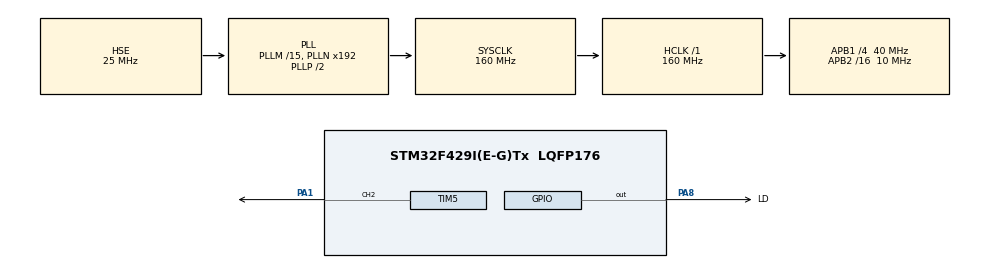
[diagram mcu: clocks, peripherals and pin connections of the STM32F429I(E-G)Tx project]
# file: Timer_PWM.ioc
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Mcu.Family=STM32F4
Mcu.Name=STM32F429I(E-G)Tx
Mcu.Package=LQFP176
NVIC.PriorityGroup=NVIC_PRIORITYGROUP_4
NVIC.TIM3_IRQn=true\:0\:0\:false\:false\:true\:true\:true
NVIC.TIM5_IRQn=true\:0\:0\:false\:false\:true\:true\:true
PA1.Signal=S_TIM5_CH2
PA13.Mode=Serial_Wire
PA13.Signal=SYS_JTMS-SWDIO
PA14.Mode=Serial_Wire
PA14.Signal=SYS_JTCK-SWCLK
PA8.GPIO_Label=LD
PA8.Signal=GPIO_Output
PH0/OSC_IN.Mode=HSE-External-Oscillator
PH0/OSC_IN.Signal=RCC_OSC_IN
PH1/OSC_OUT.Mode=HSE-External-Oscillator
PH1/OSC_OUT.Signal=RCC_OSC_OUT
ProjectManager.HeapSize=0x2000
ProjectManager.StackSize=0x4000
ProjectManager.TargetToolchain=STM32CubeIDE
RCC.48MHZClocksFreq_Value=64000000
RCC.AHBFreq_Value=160000000
RCC.APB1CLKDivider=RCC_HCLK_DIV4
RCC.APB1Freq_Value=40000000
RCC.APB1TimFreq_Value=80000000
RCC.APB2CLKDivider=RCC_HCLK_DIV16
RCC.APB2Freq_Value=10000000
RCC.APB2TimFreq_Value=20000000
RCC.CortexFreq_Value=160000000
RCC.HCLKFreq_Value=160000000
RCC.HSE_VALUE=25000000
RCC.HSI_VALUE=16000000
RCC.LSE_VALUE=32768
RCC.PLLM=15
RCC.PLLQ=5
RCC.PLLSourceVirtual=RCC_PLLSOURCE_HSE
RCC.SYSCLKFreq_VALUE=160000000
RCC.SYSCLKSource=RCC_SYSCLKSOURCE_PLLCLK
RCC.VCOOutputFreq_Value=320000000
SH.S_TIM5_CH2.0=TIM5_CH2,PWM Generation2 CH2
TIM3.Period=1599
TIM3.TIM_MasterSlaveMode=TIM_MASTERSLAVEMODE_DISABLE
TIM5.Channel-PWM\ Generation2\ CH2=TIM_CHANNEL_2
TIM5.Period=49999
TIM5.Pulse-PWM\ Generation2\ CH2=799
TIM5.TIM_MasterOutputTrigger=TIM_TRGO_UPDATE
TIM5.TIM_MasterSlaveMode=TIM_MASTERSLAVEMODE_ENABLE
VP_TIM3_VS_ClockSourceITR.Mode=TriggerSource_ITR2
VP_TIM3_VS_ControllerModeClock.Mode=Clock Mode
VP_TIM5_VS_ClockSourceINT.Mode=Internal
board=custom

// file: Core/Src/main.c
/* USER CODE BEGIN Header */
/**
  ******************************************************************************
  * @file           : main.c
  * @brief          : Main program body
  ******************************************************************************
  * @attention
  *
  * <h2><center>&copy; Copyright (c) 2021 STMicroelectronics.
  * All rights reserved.</center></h2>
  *
  * This software component is licensed by ST under Ultimate Liberty license
  * SLA0044, the "License"; You may not use this file except in compliance with
  * the License. You may obtain a copy of the License at:
  *                             www.st.com/SLA0044
  *
  ******************************************************************************
  */
/* USER CODE END Header */
#include "main.h"

TIM_HandleTypeDef htim3;
TIM_HandleTypeDef htim5;

void SystemClock_Config(void);
static void MX_GPIO_Init(void);
static void MX_TIM5_Init(void);
static void MX_TIM3_Init(void);

/* USER CODE BEGIN 0 */
//float Grap[10] = {615,    //1,194
//		302.5,			  //2,193
//		198.3,            //3,192
//		149.25,           //4,191
//		115,              //5-190
//		1230              198.3//195
//};
uint32_t Calculator_Grap_clock_num(uint8_t clock_in,float GrapUstime)
{
	return clock_in*GrapUstime;
}

void Tim_set_period(float PeriodUs)
{

	__HAL_TIM_SET_AUTORELOAD(&htim5,Calculator_Grap_clock_num(80,PeriodUs)-1);
	__HAL_TIM_SET_COUNTER(&htim5,0);
}
void Tim_set_time_high(float PeriodUs) //10s
{
	__HAL_TIM_SET_COMPARE(&htim5,TIM_CHANNEL_2,Calculator_Grap_clock_num(80,PeriodUs)-1);
}
uint8_t Time3_cnt;
void swich_new_grap()
{
	Time3_cnt ++;
	if(Time3_cnt == 196)
		Time3_cnt = 1;
	switch (Time3_cnt) {
		case 1:
		case 194:
			Tim_set_period(615+10);
			break;
		case 2:
		case 193:
			Tim_set_period(302.5+10);
			break;
		case 3:
		case 192:
			Tim_set_period(198.3+10);
			break;
		case 4:
		case 191:
			Tim_set_period(149.25+10);
			break;
		case 195:
			Tim_set_period(1230+10);
			break;
		default:
			Tim_set_period(115+10);
			break;
	}
}
void HAL_TIM_PeriodElapsedCallback(TIM_HandleTypeDef *htim)
{
	if(htim->Instance == htim3.Instance)
	{
		swich_new_grap();
		HAL_GPIO_TogglePin(LD_GPIO_Port, LD_Pin);
	}
}

/* USER CODE END 0 */

int main(void)
{

  /* MCU Configuration--------------------------------------------------------*/

  /* Reset of all peripherals, Initializes the Flash interface and the Systick. */
  HAL_Init();

  /* Configure the system clock */
  SystemClock_Config();

  /* Initialize all configured peripherals */
  MX_GPIO_Init();
  MX_TIM5_Init();
  MX_TIM3_Init();
  /* USER CODE BEGIN 2 */
  Tim_set_time_high(10);
  swich_new_grap();
  HAL_TIM_PWM_Start(&htim5, TIM_CHANNEL_2);
  HAL_TIM_Base_Start_IT(&htim3);
  /* USER CODE END 2 */

  /* Infinite loop */
  /* USER CODE BEGIN WHILE */
  while (1)
  {
	  HAL_GPIO_TogglePin(LD_GPIO_Port, LD_Pin);
	  HAL_Delay(200);
    /* USER CODE END WHILE */

  }
}

void SystemClock_Config(void)
{
  RCC_OscInitTypeDef RCC_OscInitStruct = {0};
  RCC_ClkInitTypeDef RCC_ClkInitStruct = {0};

  /** Configure the main internal regulator output voltage
  */
  __HAL_RCC_PWR_CLK_ENABLE();
  __HAL_PWR_VOLTAGESCALING_CONFIG(PWR_REGULATOR_VOLTAGE_SCALE1);
  /** Initializes the RCC Oscillators according to the specified parameters
  * in the RCC_OscInitTypeDef structure.
  */
  RCC_OscInitStruct.OscillatorType = RCC_OSCILLATORTYPE_HSE;
  RCC_OscInitStruct.HSEState = RCC_HSE_ON;
  RCC_OscInitStruct.PLL.PLLState = RCC_PLL_ON;
  RCC_OscInitStruct.PLL.PLLSource = RCC_PLLSOURCE_HSE;
  RCC_OscInitStruct.PLL.PLLM = 15;
  RCC_OscInitStruct.PLL.PLLN = 192;
  RCC_OscInitStruct.PLL.PLLP = RCC_PLLP_DIV2;
  RCC_OscInitStruct.PLL.PLLQ = 5;
  if (HAL_RCC_OscConfig(&RCC_OscInitStruct) != HAL_OK)
  {
    Error_Handler();
  }
  /** Initializes the CPU, AHB and APB buses clocks
  */
  RCC_ClkInitStruct.ClockType = RCC_CLOCKTYPE_HCLK|RCC_CLOCKTYPE_SYSCLK
                              |RCC_CLOCKTYPE_PCLK1|RCC_CLOCKTYPE_PCLK2;
  RCC_ClkInitStruct.SYSCLKSource = RCC_SYSCLKSOURCE_PLLCLK;
  RCC_ClkInitStruct.AHBCLKDivider = RCC_SYSCLK_DIV1;
  RCC_ClkInitStruct.APB1CLKDivider = RCC_HCLK_DIV4;
  RCC_ClkInitStruct.APB2CLKDivider = RCC_HCLK_DIV16;

  if (HAL_RCC_ClockConfig(&RCC_ClkInitStruct, FLASH_LATENCY_5) != HAL_OK)
  {
    Error_Handler();
  }
}

static void MX_TIM3_Init(void)
{

  TIM_SlaveConfigTypeDef sSlaveConfig = {0};
  TIM_MasterConfigTypeDef sMasterConfig = {0};

  htim3.Instance = TIM3;
  htim3.Init.Prescaler = 0;
  htim3.Init.CounterMode = TIM_COUNTERMODE_UP;
  htim3.Init.Period = 1599;
  htim3.Init.ClockDivision = TIM_CLOCKDIVISION_DIV1;
  htim3.Init.AutoReloadPreload = TIM_AUTORELOAD_PRELOAD_DISABLE;
  if (HAL_TIM_Base_Init(&htim3) != HAL_OK)
  {
    Error_Handler();
  }
  sSlaveConfig.SlaveMode = TIM_SLAVEMODE_EXTERNAL1;
  sSlaveConfig.InputTrigger = TIM_TS_ITR2;
  if (HAL_TIM_SlaveConfigSynchro(&htim3, &sSlaveConfig) != HAL_OK)
  {
    Error_Handler();
  }
  sMasterConfig.MasterOutputTrigger = TIM_TRGO_RESET;
  sMasterConfig.MasterSlaveMode = TIM_MASTERSLAVEMODE_DISABLE;
  if (HAL_TIMEx_MasterConfigSynchronization(&htim3, &sMasterConfig) != HAL_OK)
  {
    Error_Handler();
  }

}

static void MX_TIM5_Init(void)
{

  TIM_ClockConfigTypeDef sClockSourceConfig = {0};
  TIM_MasterConfigTypeDef sMasterConfig = {0};
  TIM_OC_InitTypeDef sConfigOC = {0};

  htim5.Instance = TIM5;
  htim5.Init.Prescaler = 0;
  htim5.Init.CounterMode = TIM_COUNTERMODE_UP;
  htim5.Init.Period = 49999;
  htim5.Init.ClockDivision = TIM_CLOCKDIVISION_DIV1;
  htim5.Init.AutoReloadPreload = TIM_AUTORELOAD_PRELOAD_DISABLE;
  if (HAL_TIM_Base_Init(&htim5) != HAL_OK)
  {
    Error_Handler();
  }
  sClockSourceConfig.ClockSource = TIM_CLOCKSOURCE_INTERNAL;
  if (HAL_TIM_ConfigClockSource(&htim5, &sClockSourceConfig) != HAL_OK)
  {
    Error_Handler();
  }
  if (HAL_TIM_PWM_Init(&htim5) != HAL_OK)
  {
    Error_Handler();
  }
  sMasterConfig.MasterOutputTrigger = TIM_TRGO_UPDATE;
  sMasterConfig.MasterSlaveMode = TIM_MASTERSLAVEMODE_ENABLE;
  if (HAL_TIMEx_MasterConfigSynchronization(&htim5, &sMasterConfig) != HAL_OK)
  {
    Error_Handler();
  }
  sConfigOC.OCMode = TIM_OCMODE_PWM1;
  sConfigOC.Pulse = 799;
  sConfigOC.OCPolarity = TIM_OCPOLARITY_HIGH;
  sConfigOC.OCFastMode = TIM_OCFAST_DISABLE;
  if (HAL_TIM_PWM_ConfigChannel(&htim5, &sConfigOC, TIM_CHANNEL_2) != HAL_OK)
  {
    Error_Handler();
  }
  HAL_TIM_MspPostInit(&htim5);

}

static void MX_GPIO_Init(void)
{
  GPIO_InitTypeDef GPIO_InitStruct = {0};

  /* GPIO Ports Clock Enable */
  __HAL_RCC_GPIOH_CLK_ENABLE();
  __HAL_RCC_GPIOA_CLK_ENABLE();

  /*Configure GPIO pin Output Level */
  HAL_GPIO_WritePin(LD_GPIO_Port, LD_Pin, GPIO_PIN_RESET);

  /*Configure GPIO pin : LD_Pin */
  GPIO_InitStruct.Pin = LD_Pin;
  GPIO_InitStruct.Mode = GPIO_MODE_OUTPUT_PP;
  GPIO_InitStruct.Pull = GPIO_NOPULL;
  GPIO_InitStruct.Speed = GPIO_SPEED_FREQ_LOW;
  HAL_GPIO_Init(LD_GPIO_Port, &GPIO_InitStruct);

}

void Error_Handler(void)
{
  __disable_irq();
  while (1)
  {
  }
}

/************************ (C) COPYRIGHT STMicroelectronics *****END OF FILE****/
